VERSION ""

NS_ :

BS_:

BU_: BMS Charger

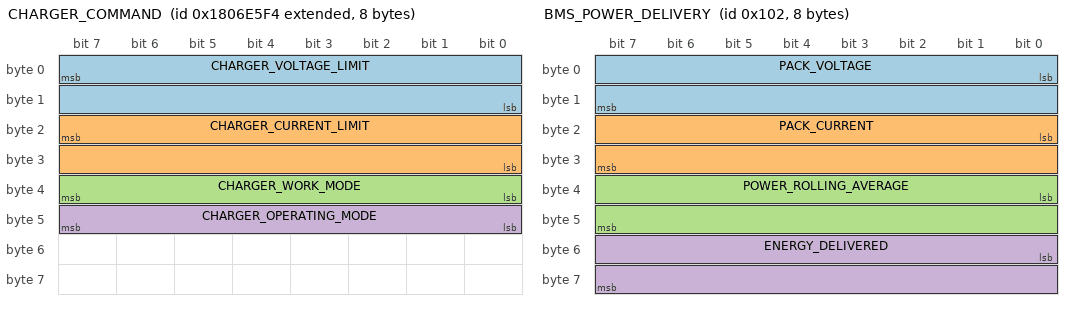
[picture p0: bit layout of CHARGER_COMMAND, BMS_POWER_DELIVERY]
BO_ 2550588916 CHARGER_COMMAND: 8 BMS
 SG_ CHARGER_VOLTAGE_LIMIT : 7|16@0+ (0.1,0) [0|680] "V" Vector__XXX
 SG_ CHARGER_CURRENT_LIMIT : 23|16@0+ (0.1,0) [0|14] "A" Vector__XXX
 SG_ CHARGER_WORK_MODE : 39|8@0+ (1,0) [0|2] "Enum" Vector__XXX
 SG_ CHARGER_OPERATING_MODE : 47|8@0+ (1,0) [0|0] "Enum" Vector__XXX

BO_ 2566869221 CHARGER_RESPONSE: 8 Charger
 SG_ CHARGE_VOLTGE_OUTPUT : 7|16@0+ (0.1,0) [0|680] "V" Vector__XXX
 SG_ CHARGER_CURRENT_OUTPUT : 23|16@0+ (0.1,0) [0|14] "A" Vector__XXX
 SG_ CHARGER_HARDWARE_PROTECTION : 32|1@0+ (1,0) [0|1] "Bool" Vector__XXX
 SG_ CHARGER_TEMPERATURE_PROTECTION : 33|1@0+ (1,0) [0|1] "Bool" Vector__XXX
 SG_ CHARGER_INPUT_VOLTAGE_STATUS : 35|2@0+ (1,0) [0|1] "Bool" Vector__XXX
 SG_ CHARGER_OUTPUT_UNDERVOLTAGE : 36|1@0+ (1,0) [0|1] "Bool" Vector__XXX
 SG_ CHARGER_OUTPUT_OVERVOLTAGE : 37|1@0+ (1,0) [0|1] "Bool" Vector__XXX
 SG_ CHARGE__OUTPUT_OVERCURRENT : 38|1@0+ (1,0) [0|1] "Bool" Vector__XXX
 SG_ CHARGER_OUTPUT_SHORT_CIRCUIT : 39|1@0+ (1,0) [0|1] "Bool" Vector__XXX
 SG_ CHARGER_COMMAND_FAULT : 40|1@0+ (1,0) [0|1] "Bool" Vector__XXX
 SG_ CHARGER_WORK_STATUS : 42|2@0+ (1,0) [0|3] "Enum" Vector__XXX
 SG_ CHARGER_INITIALIZED : 43|1@0+ (1,0) [0|1] "Bool" Vector__XXX
 SG_ CHARGER_FAN_ENABLED : 44|1@0+ (1,0) [0|1] "Bool" Vector__XXX
 SG_ CHARGER_COOLING_PUMP_ENABLED : 45|1@0+ (1,0) [0|1] "Bool" Vector__XXX
 SG_ CHARGER_CC_STATUS : 49|2@0+ (1,0) [0|3] "Enum" Vector__XXX
 SG_ CHARGER_CP_STATUS : 50|1@0+ (1,0) [0|1] "Bool" Vector__XXX
 SG_ CHARGER_SOCKET_OVERTEMPERATURE : 51|1@0+ (1,0) [0|1] "Bool" Vector__XXX
 SG_ CHARGER_ELECTRONIC_LOCK : 54|3@0+ (1,0) [0|4] "Enum" Vector__XXX
 SG_ CHARGER_S2_SWITCH_CONTROL : 55|1@0+ (1,0) [0|1] "Bool" Vector__XXX
 SG_ CHARGER_TEMPERATURE : 63|8@0+ (1,-40) [-40|205] "C" Vector__XXX

BO_ 257 BMS_STATUS: 6 BMS
 SG_ BMS_UNDERVOLTAGE_FAULT : 0|1@1+ (1,0) [0|1] "Bool" Vector__XXX
 SG_ BMS_OVERVOLTAGE_FAULT : 1|1@1+ (1,0) [0|1] "Bool" Vector__XXX
 SG_ BMS_UNDERTEMPERATURE_FAULT : 2|1@1+ (1,0) [0|1] "Bool" Vector__XXX
 SG_ BMS_OVERTEMPERATURE_FAULT : 3|1@1+ (1,0) [0|1] "Bool" Vector__XXX
 SG_ BMS_SENSE_LINE_FAULT : 4|1@1+ (1,0) [0|1] "Bool" Vector__XXX
 SG_ BMS_ISOSPI_FAULT : 5|1@1+ (1,0) [0|1] "Bool" Vector__XXX
 SG_ BMS_SELF_TEST_FAULT : 6|1@1+ (1,0) [0|1] "Bool" Vector__XXX
 SG_ BMS_LTC_0_ISOSPI_FAULT : 16|1@1+ (1,0) [0|1] "Bool" Vector__XXX
 SG_ BMS_LTC_1_ISOSPI_FAULT : 17|1@1+ (1,0) [0|1] "Bool" Vector__XXX
 SG_ BMS_LTC_2_ISOSPI_FAULT : 18|1@1+ (1,0) [0|1] "Bool" Vector__XXX
 SG_ BMS_LTC_3_ISOSPI_FAULT : 19|1@1+ (1,0) [0|1] "Bool" Vector__XXX
 SG_ BMS_LTC_4_ISOSPI_FAULT : 20|1@1+ (1,0) [0|1] "Bool" Vector__XXX
 SG_ BMS_LTC_5_ISOSPI_FAULT : 21|1@1+ (1,0) [0|1] "Bool" Vector__XXX
 SG_ BMS_LTC_6_ISOSPI_FAULT : 22|1@1+ (1,0) [0|1] "Bool" Vector__XXX
 SG_ BMS_LTC_7_ISOSPI_FAULT : 23|1@1+ (1,0) [0|1] "Bool" Vector__XXX
 SG_ BMS_LTC_8_ISOSPI_FAULT : 24|1@1+ (1,0) [0|1] "Bool" Vector__XXX
 SG_ BMS_LTC_9_ISOSPI_FAULT : 25|1@1+ (1,0) [0|1] "Bool" Vector__XXX
 SG_ BMS_LTC_10_ISOSPI_FAULT : 26|1@1+ (1,0) [0|1] "Bool" Vector__XXX
 SG_ BMS_LTC_11_ISOSPI_FAULT : 27|1@1+ (1,0) [0|1] "Bool" Vector__XXX
 SG_ BMS_LTC_0_SELF_TEST_FAULT : 32|1@1+ (1,0) [0|1] "Bool" Vector__XXX
 SG_ BMS_LTC_1_SELF_TEST_FAULT : 33|1@1+ (1,0) [0|1] "Bool" Vector__XXX
 SG_ BMS_LTC_2_SELF_TEST_FAULT : 34|1@1+ (1,0) [0|1] "Bool" Vector__XXX
 SG_ BMS_LTC_3_SELF_TEST_FAULT : 35|1@1+ (1,0) [0|1] "Bool" Vector__XXX
 SG_ BMS_LTC_4_SELF_TEST_FAULT : 36|1@1+ (1,0) [0|1] "Bool" Vector__XXX
 SG_ BMS_LTC_5_SELF_TEST_FAULT : 37|1@1+ (1,0) [0|1] "Bool" Vector__XXX
 SG_ BMS_LTC_6_SELF_TEST_FAULT : 38|1@1+ (1,0) [0|1] "Bool" Vector__XXX
 SG_ BMS_LTC_7_SELF_TEST_FAULT : 39|1@1+ (1,0) [0|1] "Bool" Vector__XXX
 SG_ BMS_LTC_8_SELF_TEST_FAULT : 40|1@1+ (1,0) [0|1] "Bool" Vector__XXX
 SG_ BMS_LTC_9_SELF_TEST_FAULT : 41|1@1+ (1,0) [0|1] "Bool" Vector__XXX
 SG_ BMS_LTC_10_SELF_TEST_FAULT : 42|1@1+ (1,0) [0|1] "Bool" Vector__XXX
 SG_ BMS_LTC_11_SELF_TEST_FAULT : 43|1@1+ (1,0) [0|1] "Bool" Vector__XXX
 SG_ BMS_CHARGING : 7|1@1+ (1,0) [0|1] "Bool" Vector__XXX
 SG_ BMS_BALANCING : 8|1@1+ (1,0) [0|1] "Bool" Vector__XXX
 SG_ SHUTDOWN_CLOSED : 9|1@1+ (1,0) [0|1] "Bool" Vector__XXX
 SG_ PRECHARGE_COMPLETE : 10|1@1+ (1,0) [0|1] "Bool" Vector__XXX
 SG_ SHUTDOWN_LOOP_BLIP : 11|1@1+ (1,0) [0|1] "Bool" Vector__XXX
 SG_ BMS_RELAY_STATUS : 12|1@1+ (1,0) [0|1] "Bool" Vector__XXX
 SG_ IMD_RELAY_STATUS : 13|1@1+ (1,0) [0|1] "Bool" Vector__XXX
 SG_ BMS_FAULT : 14|1@1+ (1,0) [0|0] "Bool" Vector__XXX

BO_ 258 BMS_POWER_DELIVERY: 8 BMS
 SG_ PACK_VOLTAGE : 0|16@1+ (0.0125,0) [0|819.2] "V" Vector__XXX
 SG_ PACK_CURRENT : 16|16@1- (0.019073486328125,0) [-625|625] "A" Vector__XXX
 SG_ POWER_ROLLING_AVERAGE : 32|16@1- (0.004,0) [-131.072|131.068] "kW" Vector__XXX
 SG_ ENERGY_DELIVERED : 48|16@1- (0.0005,0) [-16.384|16.3835] "kWh" Vector__XXX

BA_DEF_  "BusType" STRING ;
BA_DEF_DEF_  "BusType" "CAN";

CM_ SG_ 1012 CHARGER_OPERATING_MODE "Must be 0.";
